# STM32U59x register map
File version: 0.2
Registers are 32-bit, read-write, reset 0x0 unless marked. A register's access mark holds for its fields unless they carry their own. Offsets are from the block's base; [hi:lo] are bit positions; {n}, {i} and the like mark numbered series; 'fields as' and 'values as' point back to an identical list.

## OCTOSPIM — OCTOSPI I/O manager
Base 0x420C4000
Same registers: SEC_OCTOSPIM 0x520C4000
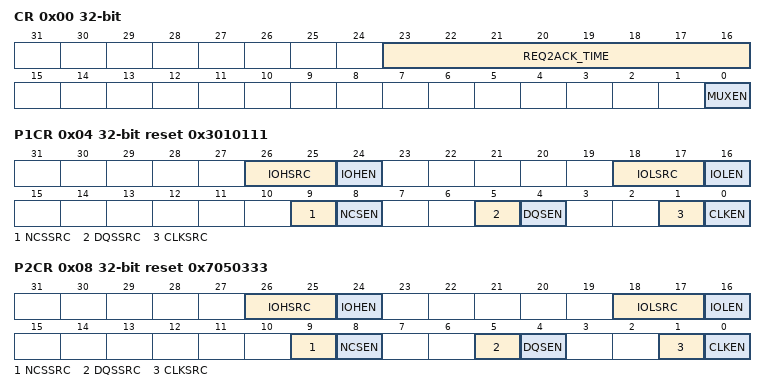
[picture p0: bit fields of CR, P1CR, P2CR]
0x00 CR — control register
  [23:16] REQ2ACK_TIME — REQ to ACK time
  [0] MUXEN — Multiplexed mode enable
0x04 P1CR reset 0x3010111 — OCTOSPI I/O manager Port 1 configuration register
  [26:25] IOHSRC — IOHSR
  [24] IOHEN
  [18:17] IOLSRC
  [16] IOLEN
  [9] NCSSRC
  [8] NCSEN
  [5] DQSSRC
  [4] DQSEN
  [1] CLKSRC
  [0] CLKEN
0x08 P2CR reset 0x7050333 — OCTOSPI I/O manager Port 2 configuration register
  fields as P1CR

## OPAMP — Operational amplifiers
Base 0x46005000
Same registers: SEC_OPAMP 0x56005000
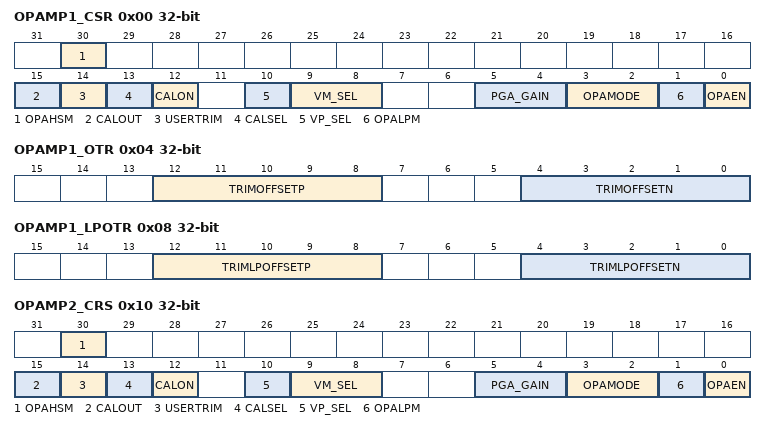
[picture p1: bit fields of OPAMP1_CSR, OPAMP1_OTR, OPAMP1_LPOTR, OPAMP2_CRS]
0x00 OPAMP1_CSR — OPAMP1 control/status register
  [30] OPAHSM
  [15] CALOUT
  [14] USERTRIM
  [13] CALSEL
  [12] CALON
  [10] VP_SEL
  [9:8] VM_SEL
  [5:4] PGA_GAIN — USERTRIM
  [3:2] OPAMODE
  [1] OPALPM
  [0] OPAEN — Operational amplifier Enable
0x04 OPAMP1_OTR — offset trimming register in normal mode
  [12:8] TRIMOFFSETP, [4:0] TRIMOFFSETN
0x08 OPAMP1_LPOTR — offset trimming register in low-power mode
  [12:8] TRIMLPOFFSETP, [4:0] TRIMLPOFFSETN
0x10 OPAMP2_CRS access per field — control/status register
  [30] OPAHSM rw, [15] CALOUT ro, [14] USERTRIM rw, [13] CALSEL rw, [12] CALON rw, [10] VP_SEL rw, [9:8] VM_SEL rw, [5:4] PGA_GAIN rw, [3:2] OPAMODE rw, [1] OPALPM rw, [0] OPAEN rw
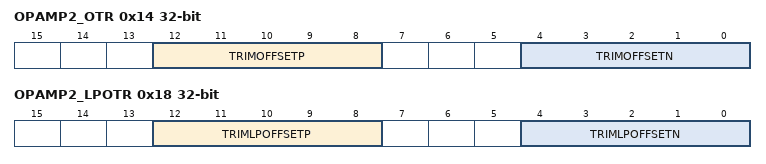
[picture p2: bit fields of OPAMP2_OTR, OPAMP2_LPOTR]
0x14 OPAMP2_OTR — offset trimming register in normal mode
  [12:8] TRIMOFFSETP, [4:0] TRIMOFFSETN
0x18 OPAMP2_LPOTR — offset trimming register in low-power mode
  [12:8] TRIMLPOFFSETP, [4:0] TRIMLPOFFSETN

## PKA — Private key accelerator
Base 0x420C2000
Same registers: SEC_PKA 0x520C2000
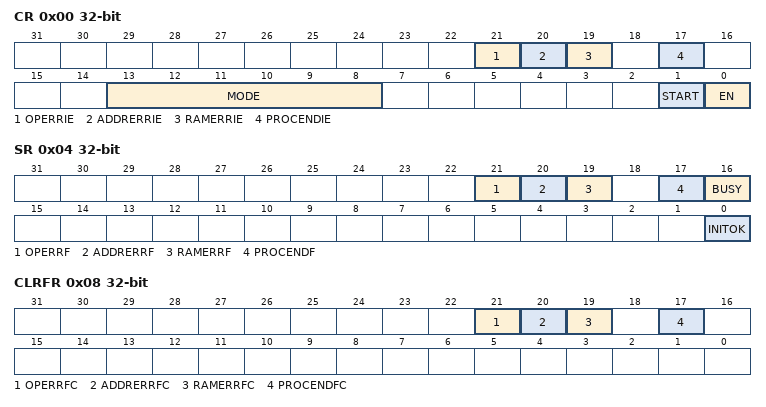
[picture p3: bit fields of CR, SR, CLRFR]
0x00 CR — Control register
  [21] OPERRIE — Operation error interrupt enable
  [20] ADDRERRIE — Address error interrupt enable
  [19] RAMERRIE — RAM error interrupt enable
  [17] PROCENDIE — End of operation interrupt enable
  [13:8] MODE — PKA Operation Mode
  [1] START — Start the operation
  [0] EN — Peripheral Enable
0x04 SR ro — PKA status register
  [21] OPERRF
  [20] ADDRERRF
  [19] RAMERRF
  [17] PROCENDF — PKA End of Operation flag
  [16] BUSY — PKA operation is in progress
  [0] INITOK
0x08 CLRFR wo — PKA clear flag register
  [21] OPERRFC
  [20] ADDRERRFC
  [19] RAMERRFC
  [17] PROCENDFC — Clear PKA End of Operation flag

## PSSI
Base 0x4202C400
Same registers: SEC_PSSI 0x5202C400
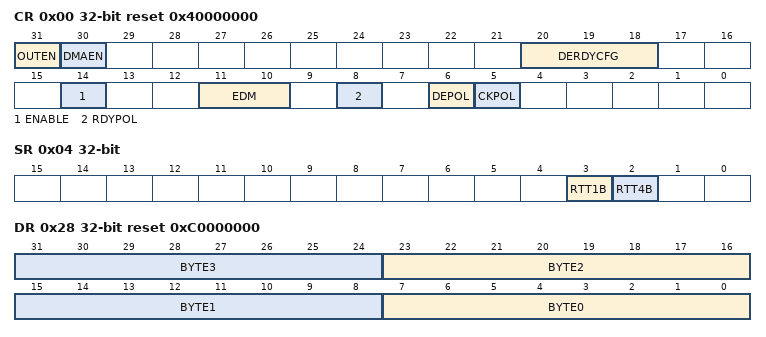
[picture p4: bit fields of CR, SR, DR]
0x00 CR reset 0x40000000 — PSSI control register
  [31] OUTEN — Data direction selection bit
  [30] DMAEN — DMA enable bit
  [20:18] DERDYCFG — Data enable and ready configuration When the PSSI_RDY function is mapped to the PSSI_DE pin (settings 101 or 111), it is still the RDYPOL bit which determines its polarity. Similarly, when the PSSI_DE function is mapped to the PSSI_RDY pin (settings 110 or 111), it is still the DEPOL bit which determines its polarity.
  [14] ENABLE — PSSI enable The contents of the FIFO are flushed when ENABLE is cleared to 0. Note: When ENABLE=1, the content of PSSI_CR must not be changed, except for the ENABLE bit itself. All configuration bits can change as soon as ENABLE changes from 0 to 1. The DMA controller and all PSSI configuration registers must be programmed correctly before setting the ENABLE bit to 1. The ENABLE bit and the DCMI ENABLE bit (bit 15 of DCMI_CR) must not be set to 1 at the same time.
  [11:10] EDM — Extended data mode
  [8] RDYPOL — Ready (PSSI_RDY) polarity This bit indicates the level on the PSSI_RDY pin when the data are not valid on the parallel interface.
  [6] DEPOL — Data enable (PSSI_DE) polarity This bit indicates the level on the PSSI_DE pin when the data are not valid on the parallel interface.
  [5] CKPOL — Parallel data clock polarity This bit configures the capture edge of the parallel clock or the edge used for driving outputs, depending on OUTEN.
0x04 SR ro — PSSI status register
  [3] RTT1B, [2] RTT4B
0x08 RIS ro — PSSI raw interrupt status register
  [1] OVR_RIS
0x0C IER — PSSI interrupt enable register
  [1] OVR_IE
0x10 MIS ro — PSSI masked interrupt status register
  [1] OVR_MIS
0x14 ICR wo — PSSI interrupt clear register
  [1] OVR_ISC
0x28 DR reset 0xC0000000 — PSSI data register
  [8n+7:8n] BYTE{n} (n=0..3) — Data byte {n}
